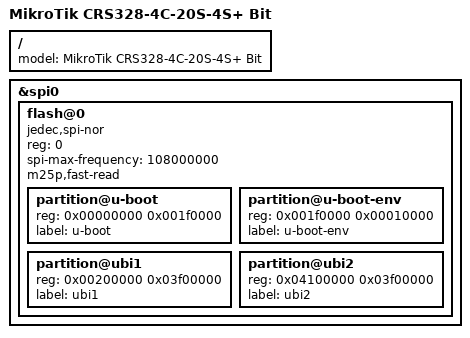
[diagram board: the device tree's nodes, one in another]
// SPDX-License-Identifier: (GPL-2.0+ OR MIT)
/*
 * Device Tree file for MikroTik CRS328-4C-20S-4S+ Bit board
 *
 * Copyright (C) 2020 Sartura Ltd.
 * Author: Luka Kovacic <luka.kovacic@sartura.hr>
 */

#include "armada-xp-crs328-4c-20s-4s.dtsi"

/ {
	model = "MikroTik CRS328-4C-20S-4S+ Bit";
};

&spi0 {
	status = "okay";

	flash@0 {
		#address-cells = <1>;
		#size-cells = <1>;
		compatible = "jedec,spi-nor";
		reg = <0>; /* Chip select 0 */
		spi-max-frequency = <108000000>;
		m25p,fast-read;

		partition@u-boot {
			reg = <0x00000000 0x001f0000>;
			label = "u-boot";
		};
		partition@u-boot-env {
			reg = <0x001f0000 0x00010000>;
			label = "u-boot-env";
		};
		partition@ubi1 {
			reg = <0x00200000 0x03f00000>;
			label = "ubi1";
		};
		partition@ubi2 {
			reg = <0x04100000 0x03f00000>;
			label = "ubi2";
		};
	};
};
